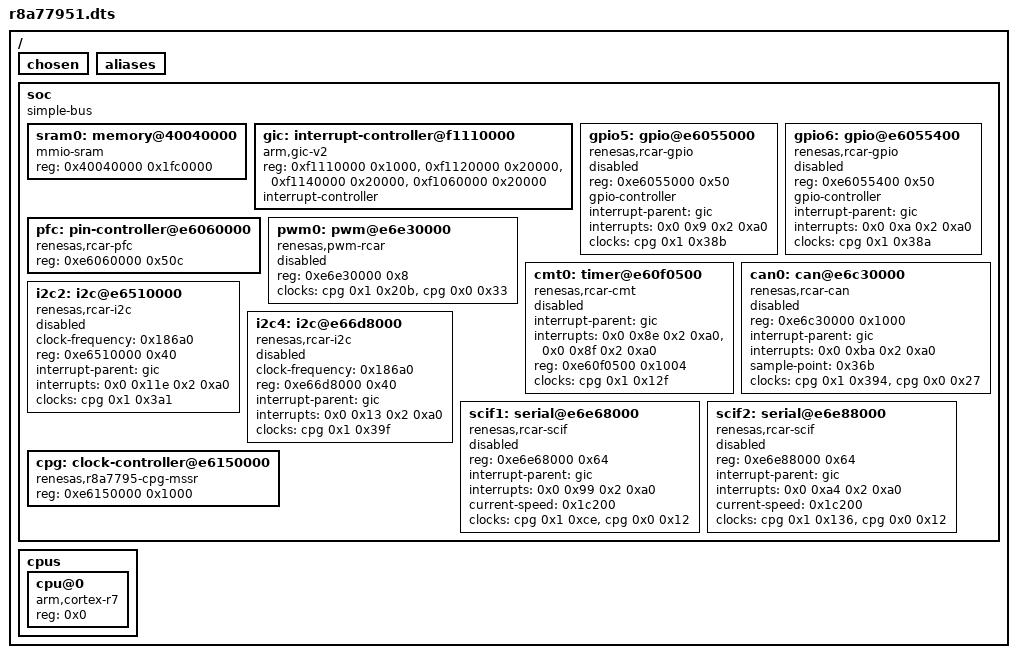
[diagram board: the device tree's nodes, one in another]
/dts-v1/;

/ {
	#address-cells = < 0x1 >;
	#size-cells = < 0x1 >;
	chosen {
	};
	aliases {
	};
	soc {
		#address-cells = < 0x1 >;
		#size-cells = < 0x1 >;
		compatible = "simple-bus";
		ranges;
		sram0: memory@40040000 {
			compatible = "mmio-sram";
			reg = < 0x40040000 0x1fc0000 >;
		};
		gic: interrupt-controller@f1110000 {
			compatible = "arm,gic-v2", "arm,gic";
			reg = < 0xf1110000 0x1000 >, < 0xf1120000 0x20000 >, < 0xf1140000 0x20000 >, < 0xf1060000 0x20000 >;
			interrupt-controller;
			#interrupt-cells = < 0x4 >;
			status = "okay";
			phandle = < 0x1 >;
		};
		gpio5: gpio@e6055000 {
			compatible = "renesas,rcar-gpio";
			reg = < 0xe6055000 0x50 >;
			#gpio-cells = < 0x2 >;
			gpio-controller;
			interrupt-parent = < &gic >;
			interrupts = < 0x0 0x9 0x2 0xa0 >;
			clocks = < &cpg 0x1 0x38b >;
			status = "disabled";
		};
		gpio6: gpio@e6055400 {
			compatible = "renesas,rcar-gpio";
			reg = < 0xe6055400 0x50 >;
			#gpio-cells = < 0x2 >;
			gpio-controller;
			interrupt-parent = < &gic >;
			interrupts = < 0x0 0xa 0x2 0xa0 >;
			clocks = < &cpg 0x1 0x38a >;
			status = "disabled";
		};
		pfc: pin-controller@e6060000 {
			compatible = "renesas,rcar-pfc";
			reg = < 0xe6060000 0x50c >;
		};
		pwm0: pwm@e6e30000 {
			compatible = "renesas,pwm-rcar";
			reg = < 0xe6e30000 0x8 >;
			#pwm-cells = < 0x3 >;
			status = "disabled";
			clocks = < &cpg 0x1 0x20b >, < &cpg 0x0 0x33 >;
		};
		cmt0: timer@e60f0500 {
			compatible = "renesas,rcar-cmt";
			interrupt-parent = < &gic >;
			interrupts = < 0x0 0x8e 0x2 0xa0 >, < 0x0 0x8f 0x2 0xa0 >;
			interrupt-names = "irq_0", "irq_1";
			reg = < 0xe60f0500 0x1004 >;
			clocks = < &cpg 0x1 0x12f >;
			status = "disabled";
		};
		can0: can@e6c30000 {
			compatible = "renesas,rcar-can";
			reg = < 0xe6c30000 0x1000 >;
			interrupt-parent = < &gic >;
			interrupts = < 0x0 0xba 0x2 0xa0 >;
			sample-point = < 0x36b >;
			status = "disabled";
			clocks = < &cpg 0x1 0x394 >, < &cpg 0x0 0x27 >;
		};
		i2c2: i2c@e6510000 {
			compatible = "renesas,rcar-i2c";
			clock-frequency = < 0x186a0 >;
			#address-cells = < 0x1 >;
			#size-cells = < 0x0 >;
			reg = < 0xe6510000 0x40 >;
			interrupt-parent = < &gic >;
			interrupts = < 0x0 0x11e 0x2 0xa0 >;
			clocks = < &cpg 0x1 0x3a1 >;
			status = "disabled";
		};
		i2c4: i2c@e66d8000 {
			compatible = "renesas,rcar-i2c";
			clock-frequency = < 0x186a0 >;
			#address-cells = < 0x1 >;
			#size-cells = < 0x0 >;
			reg = < 0xe66d8000 0x40 >;
			interrupt-parent = < &gic >;
			interrupts = < 0x0 0x13 0x2 0xa0 >;
			clocks = < &cpg 0x1 0x39f >;
			status = "disabled";
		};
		scif1: serial@e6e68000 {
			compatible = "renesas,rcar-scif";
			reg = < 0xe6e68000 0x64 >;
			interrupt-parent = < &gic >;
			interrupts = < 0x0 0x99 0x2 0xa0 >;
			current-speed = < 0x1c200 >;
			status = "disabled";
			clocks = < &cpg 0x1 0xce >, < &cpg 0x0 0x12 >;
		};
		scif2: serial@e6e88000 {
			compatible = "renesas,rcar-scif";
			reg = < 0xe6e88000 0x64 >;
			interrupt-parent = < &gic >;
			interrupts = < 0x0 0xa4 0x2 0xa0 >;
			current-speed = < 0x1c200 >;
			status = "disabled";
			clocks = < &cpg 0x1 0x136 >, < &cpg 0x0 0x12 >;
		};
		cpg: clock-controller@e6150000 {
			compatible = "renesas,r8a7795-cpg-mssr";
			reg = < 0xe6150000 0x1000 >;
			#clock-cells = < 0x2 >;
			phandle = < 0x2 >;
		};
	};
	cpus {
		#address-cells = < 0x1 >;
		#size-cells = < 0x0 >;
		cpu@0 {
			device_type = "cpu";
			compatible = "arm,cortex-r7";
			reg = < 0x0 >;
		};
	};
};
